VERSION ""

NS_ :

BS_:

BU_: XXX

BO_ 597 NEW_MSG_1: 8 XXX

BO_ 336 NEW_MSG_2: 8 XXX
 SG_ Speed-good : 29|11@0+ (1,0) [0|2047] "" XXX
 SG_ Interesting1 : 55|8@0+ (1,0) [0|255] "" XXX

BO_ 32 NEW_MSG_3: 8 XXX

BO_ 341 NEW_MSG_4: 8 XXX

BO_ 337 NEW_MSG_5: 8 XXX

BO_ 340 NEW_MSG_6: 8 XXX

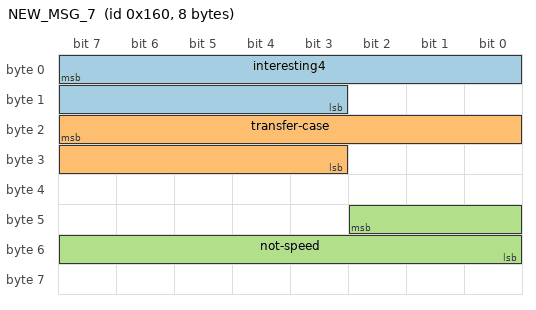
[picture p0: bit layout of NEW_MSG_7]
BO_ 352 NEW_MSG_7: 8 XXX
 SG_ interesting4 : 7|13@0+ (1,0) [0|8191] "" XXX
 SG_ transfer-case : 23|13@0+ (1,0) [0|8191] "" XXX
 SG_ not-speed : 42|11@0+ (1,0) [0|2047] "" XXX

BO_ 1056 NEW_MSG_8: 8 XXX
 SG_ NEW_SIGNAL_1 : 55|8@0+ (1,0) [0|255] "" XXX

BO_ 1044 NEW_MSG_9: 8 XXX
 SG_ engine-rpm : 50|11@0+ (1,0) [0|7000] "rpm" XXX
